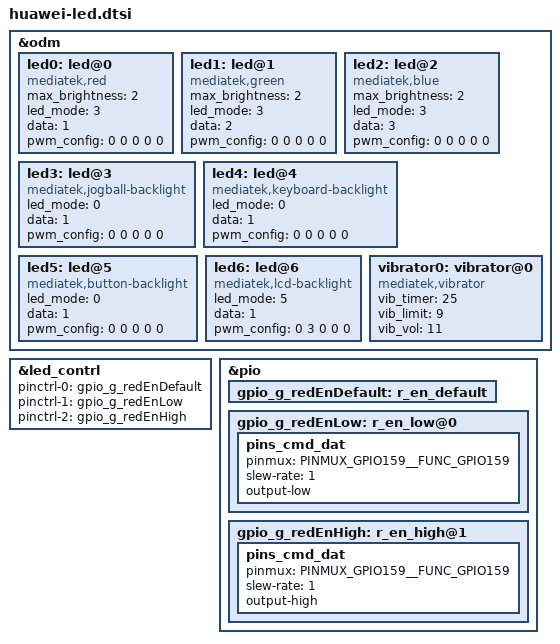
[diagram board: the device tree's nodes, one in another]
&odm {
	led0:led@0 {
		compatible = "mediatek,red";
		max_brightness = <2>;
		led_mode = <3>;
		data = <1>;
		pwm_config = <0 0 0 0 0>;
	};
	led1:led@1 {
		compatible = "mediatek,green";
		max_brightness = <2>;
		led_mode = <3>;
		data = <2>;
		pwm_config = <0 0 0 0 0>;
	};
	led2:led@2 {
		compatible = "mediatek,blue";
		max_brightness = <2>;
		led_mode = <3>;
		data = <3>;
		pwm_config = <0 0 0 0 0>;
	};
	led3:led@3 {
		compatible = "mediatek,jogball-backlight";
		led_mode = <0>;
		data = <1>;
		pwm_config = <0 0 0 0 0>;
	};
	led4:led@4 {
		compatible = "mediatek,keyboard-backlight";
		led_mode = <0>;
		data = <1>;
		pwm_config = <0 0 0 0 0>;
	};
	led5:led@5 {
		compatible = "mediatek,button-backlight";
		led_mode = <0>;
		data = <1>;
		pwm_config = <0 0 0 0 0>;
	};
	led6:led@6 {
		compatible = "mediatek,lcd-backlight";
		led_mode = <5>;
		data = <1>;
		pwm_config = <0 3 0 0 0>;
	};
	vibrator0:vibrator@0 {
		compatible = "mediatek,vibrator";
		vib_timer = <25>;
		vib_limit = <9>;
		vib_vol= <11>;
	};
};

&led_contrl {
	pinctrl-names = "g_redEnDefault", "g_redEnLow", "g_redEnHigh";
	pinctrl-0 = <&gpio_g_redEnDefault>;
	pinctrl-1 = <&gpio_g_redEnLow>;
	pinctrl-2 = <&gpio_g_redEnHigh>;
	status = "okay";
};

&pio {
	/* IRTX GPIO Settings -Start */
	/* default: GPIO0, output, high */
	gpio_g_redEnDefault: r_en_default {
	};
	gpio_g_redEnLow: r_en_low@0{
		pins_cmd_dat {
			pinmux = <PINMUX_GPIO159__FUNC_GPIO159>;
			slew-rate = <1>;
			output-low;
		};
	};
	gpio_g_redEnHigh: r_en_high@1 {
		pins_cmd_dat {
			pinmux = <PINMUX_GPIO159__FUNC_GPIO159>;
			slew-rate = <1>;
			output-high;
		};
	};
};


